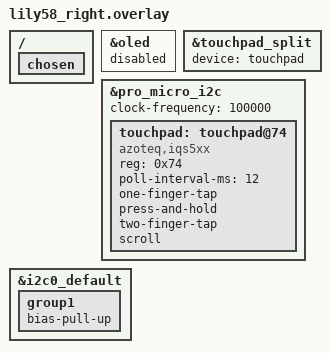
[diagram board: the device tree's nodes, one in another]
#include "touchpad.dtsi"

/ {
    chosen {
        /delete-property/ zephyr,display;
    };
};

/* The nice!view is removed from this half, and the stock lily58 OLED node would sit on the touchpad's I2C bus. */
&oled {
    status = "disabled";
};

&touchpad_split {
    device = <&touchpad>;
};

&pro_micro_i2c {
    status = "okay";

    /* TEST: 100 kHz. The bus runs on the nRF's weak internal pull-ups, so fast mode edges may be too slow. */
    clock-frequency = <100000>;

    touchpad: touchpad@74 {
        compatible = "azoteq,iqs5xx";
        reg = <0x74>;

        /* No rdy-gpios or reset-gpios on this adapter, so the driver polls. */
        poll-interval-ms = <12>;

        one-finger-tap;
        press-and-hold;
        two-finger-tap;
        scroll;
    };
};

/* Enable the nRF's internal pull-ups on SDA/SCL in case the adapter has none. */
&i2c0_default {
    group1 {
        bias-pull-up;
    };
};
